AUTOSAR XML (schema 4-2-2)
package /ComponentTypes
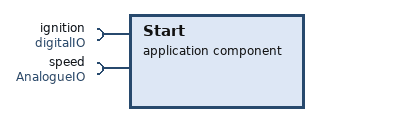
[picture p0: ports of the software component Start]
  application sw component type Start
    require port ignition: required-interface=digitalIO
    require port speed: required-interface=AnalogueIO
    behavior Start_InternalBehavior
      port-api-options:
        enable-take-address=true, error-handling=NO-TRANSFORMER-ERROR-HANDLING, indirect-api=true, port=ignition
        enable-take-address=true, error-handling=NO-TRANSFORMER-ERROR-HANDLING, indirect-api=true, port=speed
  swc implementation Start_Implementation: behavior=Start_InternalBehavior
